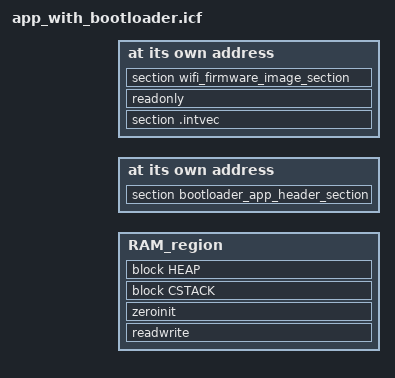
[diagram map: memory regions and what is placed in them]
/*
 * Copyright 2018, Cypress Semiconductor Corporation or a subsidiary of 
 * Cypress Semiconductor Corporation. All Rights Reserved.
 * 
 * This software, associated documentation and materials ("Software"),
 * is owned by Cypress Semiconductor Corporation
 * or one of its subsidiaries ("Cypress") and is protected by and subject to
 * worldwide patent protection (United States and foreign),
 * United States copyright laws and international treaty provisions.
 * Therefore, you may use this Software only as provided in the license
 * agreement accompanying the software package from which you
 * obtained this Software ("EULA").
 * If no EULA applies, Cypress hereby grants you a personal, non-exclusive,
 * non-transferable license to copy, modify, and compile the Software
 * source code solely for use in connection with Cypress's
 * integrated circuit products. Any reproduction, modification, translation,
 * compilation, or representation of this Software except as specified
 * above is prohibited without the express written permission of Cypress.
 *
 * Disclaimer: THIS SOFTWARE IS PROVIDED AS-IS, WITH NO WARRANTY OF ANY KIND,
 * EXPRESS OR IMPLIED, INCLUDING, BUT NOT LIMITED TO, NONINFRINGEMENT, IMPLIED
 * WARRANTIES OF MERCHANTABILITY AND FITNESS FOR A PARTICULAR PURPOSE. Cypress
 * reserves the right to make changes to the Software without notice. Cypress
 * does not assume any liability arising out of the application or use of the
 * Software or any product or circuit described in the Software. Cypress does
 * not authorize its products for use in any products where a malfunction or
 * failure of the Cypress product may reasonably be expected to result in
 * significant property damage, injury or death ("High Risk Product"). By
 * including Cypress's product in a High Risk Product, the manufacturer
 * of such system or application assumes all risk of such use and in doing
 * so agrees to indemnify Cypress against all liability.
 */

/* Define memory symbols */
include "memory_with_bootloader.icf";

/* Define memory regions */
define memory mem with size = 4G;
define region ROM_region   = mem:[from __Bootloader_vector_start   to __App_end];
define region RAM_region   = mem:[from __SRAM_start   to __SRAM_end];


/* create a stack block */
define block CSTACK    with alignment = 8, size = __STACKSIZE__   { };
/* create a heap block */
define block HEAP      with alignment = 8, size = __HEAPSIZE__    { };

/* place application header */
place at address mem:__App_header_start   { section bootloader_app_header_section };

keep {section bootloader_app_header_section};

/* place application and its data */
place at address mem:(__App_start ) { section .intvec, readonly, section wifi_firmware_image_section };

initialize by copy { readwrite };


place in RAM_region   { readwrite,
                        zeroinit,
                        block CSTACK,
                        block HEAP,
                      };

/* export symbols */
define symbol bootloader_api_addr_loc = __Bootloader_apis_start;
export symbol bootloader_api_addr_loc;

/* vectors offset */
define symbol vectors_offset = __App_start -  __App_header_start;
export symbol vectors_offset;

define symbol app_hdr_start_addr_loc = __App_header_start;
export symbol app_hdr_start_addr_loc;

define symbol dct1_start_addr_loc = __DCT1_start;
export symbol dct1_start_addr_loc;

define symbol dct1_size_loc = __DCT1_length;
export symbol dct1_size_loc;

define symbol dct2_start_addr_loc = __DCT2_start;
export symbol dct2_start_addr_loc;

define symbol dct2_size_loc = __DCT2_length;
export symbol dct2_size_loc;



